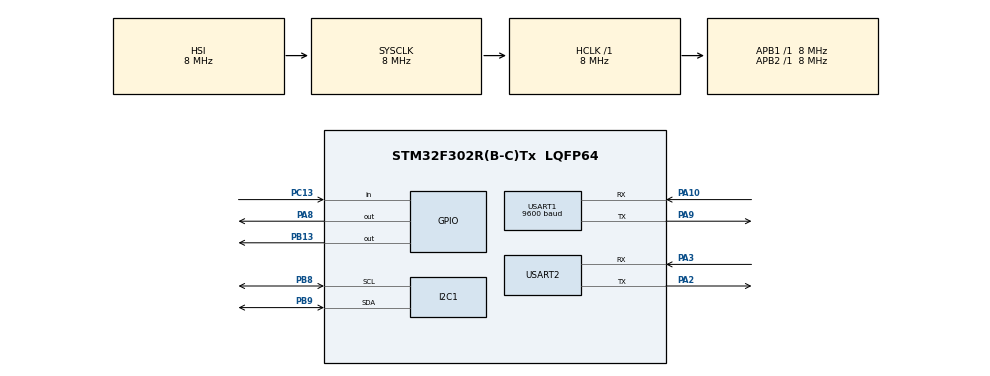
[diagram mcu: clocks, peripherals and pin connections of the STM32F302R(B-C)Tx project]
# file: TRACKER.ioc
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I2C1.Timing=0x2000090E
Mcu.Family=STM32F3
Mcu.Name=STM32F302R(B-C)Tx
Mcu.Package=LQFP64
NVIC.PriorityGroup=NVIC_PRIORITYGROUP_4
NVIC.RCC_IRQn=true\:0\:0\:false\:false\:true
NVIC.USART1_IRQn=true\:0\:0\:false\:false\:true
NVIC.USART2_IRQn=true\:0\:0\:false\:false\:true
PA10.Mode=Asynchronous
PA10.Signal=USART1_RX
PA2.Mode=Asynchronous
PA2.Signal=USART2_TX
PA3.Mode=Asynchronous
PA3.Signal=USART2_RX
PA8.Signal=GPIO_Output
PA9.Mode=Asynchronous
PA9.Signal=USART1_TX
PB13.Signal=GPIO_Output
PB8.Mode=I2C
PB8.Signal=I2C1_SCL
PB9.Mode=I2C
PB9.Signal=I2C1_SDA
PC13.Signal=GPIO_Input
ProjectManager.HeapSize=0x200
ProjectManager.StackSize=0x400
ProjectManager.TargetToolchain=MDK-ARM V5
RCC.AHBFreq_Value=8000000
RCC.APB1Freq_Value=8000000
RCC.APB2Freq_Value=8000000
RCC.CortexFreq_Value=8000000
RCC.HSE_VALUE=8000000
RCC.HSI_VALUE=8000000
RCC.LSE_VALUE=32768
RCC.SYSCLKFreq_VALUE=8000000
USART1.BaudRate=9600
board=TRACKER

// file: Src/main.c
/**
  ******************************************************************************
  * File Name          : main.c
  * Description        : Main program body
  ******************************************************************************
  *
  * COPYRIGHT(c) 2017 STMicroelectronics
  *
  * Redistribution and use in source and binary forms, with or without modification,
  * are permitted provided that the following conditions are met:
  *   1. Redistributions of source code must retain the above copyright notice,
  *      this list of conditions and the following disclaimer.
  *   2. Redistributions in binary form must reproduce the above copyright notice,
  *      this list of conditions and the following disclaimer in the documentation
  *      and/or other materials provided with the distribution.
  *   3. Neither the name of STMicroelectronics nor the names of its contributors
  *      may be used to endorse or promote products derived from this software
  *      without specific prior written permission.
  *
  * THIS SOFTWARE IS PROVIDED BY THE COPYRIGHT HOLDERS AND CONTRIBUTORS "AS IS"
  * AND ANY EXPRESS OR IMPLIED WARRANTIES, INCLUDING, BUT NOT LIMITED TO, THE
  * IMPLIED WARRANTIES OF MERCHANTABILITY AND FITNESS FOR A PARTICULAR PURPOSE ARE
  * DISCLAIMED. IN NO EVENT SHALL THE COPYRIGHT HOLDER OR CONTRIBUTORS BE LIABLE
  * FOR ANY DIRECT, INDIRECT, INCIDENTAL, SPECIAL, EXEMPLARY, OR CONSEQUENTIAL
  * DAMAGES (INCLUDING, BUT NOT LIMITED TO, PROCUREMENT OF SUBSTITUTE GOODS OR
  * SERVICES; LOSS OF USE, DATA, OR PROFITS; OR BUSINESS INTERRUPTION) HOWEVER
  * CAUSED AND ON ANY THEORY OF LIABILITY, WHETHER IN CONTRACT, STRICT LIABILITY,
  * OR TORT (INCLUDING NEGLIGENCE OR OTHERWISE) ARISING IN ANY WAY OUT OF THE USE
  * OF THIS SOFTWARE, EVEN IF ADVISED OF THE POSSIBILITY OF SUCH DAMAGE.
  *
  ******************************************************************************
  */
#include "main.h"
#include "stm32f3xx_hal.h"

/* USER CODE BEGIN Includes */

#include "uart_printf.h"
#include "program.h"

/* USER CODE END Includes */

I2C_HandleTypeDef hi2c1;

UART_HandleTypeDef huart1;
UART_HandleTypeDef huart2;

/* USER CODE BEGIN PV */
/* Private variables ---------------------------------------------------------*/

/* USER CODE END PV */

void SystemClock_Config(void);
void Error_Handler(void);
static void MX_GPIO_Init(void);
static void MX_USART2_UART_Init(void);
static void MX_I2C1_Init(void);
static void MX_USART1_UART_Init(void);

/* USER CODE BEGIN PFP */
/* Private function prototypes -----------------------------------------------*/

/* USER CODE END PFP */

/* USER CODE BEGIN 0 */

void  MAIN_GPIO_Init(void) {
	MX_GPIO_Init();
}

void MAIN_USART2_UART_Init(void) {
	MX_USART2_UART_Init();
}

void  MAIN_I2C1_Init(void) {
	MX_I2C1_Init();
}

void  MAIN_USART1_UART_Init(void) {
	MX_USART1_UART_Init();
}

/* USER CODE END 0 */

int main(void)
{

  /* MCU Configuration----------------------------------------------------------*/

  /* Reset of all peripherals, Initializes the Flash interface and the Systick. */
  HAL_Init();

  /* Configure the system clock */
  SystemClock_Config();

  /* Initialize all configured peripherals */
  MX_GPIO_Init();
  MX_USART2_UART_Init();
  MX_I2C1_Init();
  MX_USART1_UART_Init();

  /* USER CODE BEGIN 2 */

	printf("After init peripherals\n");

	program_setup();

  /* USER CODE END 2 */

  /* Infinite loop */
  /* USER CODE BEGIN WHILE */
  while (1)
  {

		program_loop();

  /* USER CODE END WHILE */

  }

}

/** System Clock Configuration
*/
void SystemClock_Config(void)
{

  RCC_OscInitTypeDef RCC_OscInitStruct;
  RCC_ClkInitTypeDef RCC_ClkInitStruct;
  RCC_PeriphCLKInitTypeDef PeriphClkInit;

    /**Initializes the CPU, AHB and APB busses clocks
    */
  RCC_OscInitStruct.OscillatorType = RCC_OSCILLATORTYPE_HSI;
  RCC_OscInitStruct.HSIState = RCC_HSI_ON;
  RCC_OscInitStruct.HSICalibrationValue = 16;
  RCC_OscInitStruct.PLL.PLLState = RCC_PLL_NONE;
  if (HAL_RCC_OscConfig(&RCC_OscInitStruct) != HAL_OK)
  {
    Error_Handler();
  }

    /**Initializes the CPU, AHB and APB busses clocks
    */
  RCC_ClkInitStruct.ClockType = RCC_CLOCKTYPE_HCLK|RCC_CLOCKTYPE_SYSCLK
                              |RCC_CLOCKTYPE_PCLK1|RCC_CLOCKTYPE_PCLK2;
  RCC_ClkInitStruct.SYSCLKSource = RCC_SYSCLKSOURCE_HSI;
  RCC_ClkInitStruct.AHBCLKDivider = RCC_SYSCLK_DIV1;
  RCC_ClkInitStruct.APB1CLKDivider = RCC_HCLK_DIV1;
  RCC_ClkInitStruct.APB2CLKDivider = RCC_HCLK_DIV1;

  if (HAL_RCC_ClockConfig(&RCC_ClkInitStruct, FLASH_LATENCY_0) != HAL_OK)
  {
    Error_Handler();
  }

  PeriphClkInit.PeriphClockSelection = RCC_PERIPHCLK_USART1|RCC_PERIPHCLK_USART2
                              |RCC_PERIPHCLK_I2C1;
  PeriphClkInit.Usart1ClockSelection = RCC_USART1CLKSOURCE_PCLK2;
  PeriphClkInit.Usart2ClockSelection = RCC_USART2CLKSOURCE_PCLK1;
  PeriphClkInit.I2c1ClockSelection = RCC_I2C1CLKSOURCE_HSI;
  if (HAL_RCCEx_PeriphCLKConfig(&PeriphClkInit) != HAL_OK)
  {
    Error_Handler();
  }

    /**Configure the Systick interrupt time
    */
  HAL_SYSTICK_Config(HAL_RCC_GetHCLKFreq()/1000);

    /**Configure the Systick
    */
  HAL_SYSTICK_CLKSourceConfig(SYSTICK_CLKSOURCE_HCLK);

  /* SysTick_IRQn interrupt configuration */
  HAL_NVIC_SetPriority(SysTick_IRQn, 0, 0);
}

/* I2C1 init function */
static void MX_I2C1_Init(void)
{

  hi2c1.Instance = I2C1;
  hi2c1.Init.Timing = 0x2000090E;
  hi2c1.Init.OwnAddress1 = 0;
  hi2c1.Init.AddressingMode = I2C_ADDRESSINGMODE_7BIT;
  hi2c1.Init.DualAddressMode = I2C_DUALADDRESS_DISABLE;
  hi2c1.Init.OwnAddress2 = 0;
  hi2c1.Init.OwnAddress2Masks = I2C_OA2_NOMASK;
  hi2c1.Init.GeneralCallMode = I2C_GENERALCALL_DISABLE;
  hi2c1.Init.NoStretchMode = I2C_NOSTRETCH_DISABLE;
  if (HAL_I2C_Init(&hi2c1) != HAL_OK)
  {
    Error_Handler();
  }

    /**Configure Analogue filter
    */
  if (HAL_I2CEx_ConfigAnalogFilter(&hi2c1, I2C_ANALOGFILTER_ENABLE) != HAL_OK)
  {
    Error_Handler();
  }

}

/* USART1 init function */
static void MX_USART1_UART_Init(void)
{

  huart1.Instance = USART1;
  huart1.Init.BaudRate = 9600;
  huart1.Init.WordLength = UART_WORDLENGTH_8B;
  huart1.Init.StopBits = UART_STOPBITS_1;
  huart1.Init.Parity = UART_PARITY_NONE;
  huart1.Init.Mode = UART_MODE_TX_RX;
  huart1.Init.HwFlowCtl = UART_HWCONTROL_NONE;
  huart1.Init.OverSampling = UART_OVERSAMPLING_16;
  huart1.Init.OneBitSampling = UART_ONE_BIT_SAMPLE_DISABLE;
  huart1.AdvancedInit.AdvFeatureInit = UART_ADVFEATURE_NO_INIT;
  if (HAL_UART_Init(&huart1) != HAL_OK)
  {
    Error_Handler();
  }

}

/* USART2 init function */
static void MX_USART2_UART_Init(void)
{

  huart2.Instance = USART2;
  huart2.Init.BaudRate = 38400;
  huart2.Init.WordLength = UART_WORDLENGTH_8B;
  huart2.Init.StopBits = UART_STOPBITS_1;
  huart2.Init.Parity = UART_PARITY_NONE;
  huart2.Init.Mode = UART_MODE_TX_RX;
  huart2.Init.HwFlowCtl = UART_HWCONTROL_NONE;
  huart2.Init.OverSampling = UART_OVERSAMPLING_16;
  huart2.Init.OneBitSampling = UART_ONE_BIT_SAMPLE_DISABLE;
  huart2.AdvancedInit.AdvFeatureInit = UART_ADVFEATURE_NO_INIT;
  if (HAL_UART_Init(&huart2) != HAL_OK)
  {
    Error_Handler();
  }

}

/** Configure pins as
        * Analog
        * Input
        * Output
        * EVENT_OUT
        * EXTI
*/
static void MX_GPIO_Init(void)
{

  GPIO_InitTypeDef GPIO_InitStruct;

  /* GPIO Ports Clock Enable */
  __HAL_RCC_GPIOC_CLK_ENABLE();
  __HAL_RCC_GPIOA_CLK_ENABLE();
  __HAL_RCC_GPIOB_CLK_ENABLE();

  /*Configure GPIO pin Output Level */
  HAL_GPIO_WritePin(GPIOB, GPIO_PIN_13, GPIO_PIN_RESET);

  /*Configure GPIO pin Output Level */
  HAL_GPIO_WritePin(GPIOA, GPIO_PIN_8, GPIO_PIN_RESET);

  /*Configure GPIO pin : PC13 */
  GPIO_InitStruct.Pin = GPIO_PIN_13;
  GPIO_InitStruct.Mode = GPIO_MODE_INPUT;
  GPIO_InitStruct.Pull = GPIO_NOPULL;
  HAL_GPIO_Init(GPIOC, &GPIO_InitStruct);

  /*Configure GPIO pin : PB13 */
  GPIO_InitStruct.Pin = GPIO_PIN_13;
  GPIO_InitStruct.Mode = GPIO_MODE_OUTPUT_PP;
  GPIO_InitStruct.Pull = GPIO_NOPULL;
  GPIO_InitStruct.Speed = GPIO_SPEED_FREQ_LOW;
  HAL_GPIO_Init(GPIOB, &GPIO_InitStruct);

  /*Configure GPIO pin : PA8 */
  GPIO_InitStruct.Pin = GPIO_PIN_8;
  GPIO_InitStruct.Mode = GPIO_MODE_OUTPUT_PP;
  GPIO_InitStruct.Pull = GPIO_NOPULL;
  GPIO_InitStruct.Speed = GPIO_SPEED_FREQ_LOW;
  HAL_GPIO_Init(GPIOA, &GPIO_InitStruct);

}

void Error_Handler(void)
{
  while(1)
  {
  }
}

/************************ (C) COPYRIGHT STMicroelectronics *****END OF FILE****/
